VERSION ""

NS_ :

BS_:

BU_: IVI GTW IC HUD DVR WCM PDC VSP SVC TBOX_INFO SVM

BO_ 1957 Diag_Resp_IVI: 8 IVI
 SG_ Diag_Resp_IVI_Data : 0|64@1+ (1,0) [0|0] "N/A"  GTW

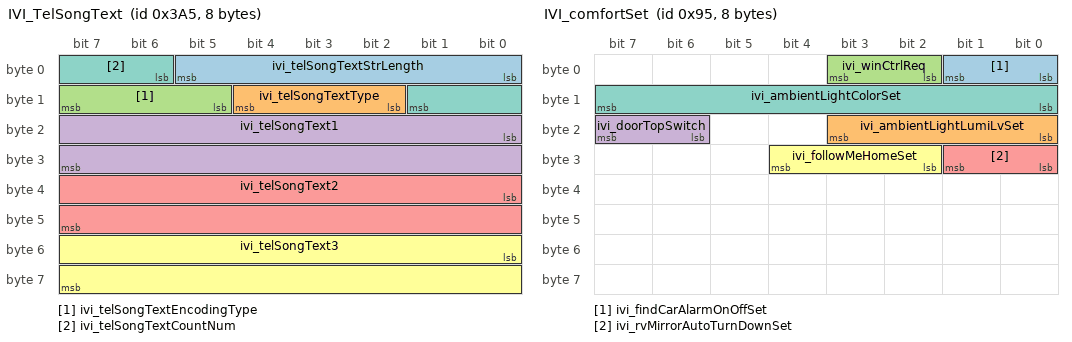
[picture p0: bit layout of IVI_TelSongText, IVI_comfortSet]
BO_ 933 IVI_TelSongText: 8 IVI
 SG_ ivi_telSongTextStrLength : 0|6@1+ (1,0) [0|63] ""  IC,HUD
 SG_ ivi_telSongTextType : 10|3@1+ (1,0) [0|7] ""  IC,HUD
 SG_ ivi_telSongTextEncodingType : 13|3@1+ (1,0) [0|7] ""  IC,HUD
 SG_ ivi_telSongText1 : 16|16@1+ (1,0) [0|65535] ""  IC,HUD
 SG_ ivi_telSongText2 : 32|16@1+ (1,0) [0|65535] ""  IC,HUD
 SG_ ivi_telSongText3 : 48|16@1+ (1,0) [0|65535] ""  IC,HUD
 SG_ ivi_telSongTextCountNum : 6|4@1+ (1,0) [0|15] ""  IC,HUD

BO_ 437 IVI_chassisSet: 8 IVI
 SG_ ivi_epsModeSet : 0|2@1+ (1,0) [0|3] ""  GTW
 SG_ ivi_lkaSensitivitySet : 10|2@1+ (1,0) [0|3] ""  GTW
 SG_ ivi_lcaBsdOnOffSet : 12|2@1+ (1,0) [0|3] ""  GTW
 SG_ ivi_rctaOnOffSet : 14|2@1+ (1,0) [0|3] ""  GTW
 SG_ ivi_dowOnOffSet : 16|2@1+ (1,0) [0|3] ""  GTW
 SG_ ivi_escOffSw : 2|2@1+ (1,0) [0|3] ""  GTW
 SG_ ivi_laneAssistFuncSet : 22|2@1+ (1,0) [0|3] ""  GTW
 SG_ ivi_hmaOnOffSet : 24|2@1+ (1,0) [0|3] ""  GTW
 SG_ ivi_slaOnOffSet : 26|2@1+ (1,0) [0|3] ""  GTW
 SG_ ivi_currentRoadType : 28|4@1+ (1,0) [0|15] ""  GTW
 SG_ ivi_countryCodeSet : 32|8@1+ (1,0) [0|255] ""  GTW
 SG_ ivi_hdcOnOffSet : 4|2@1+ (1,0) [0|3] ""  GTW
 SG_ ivi_speedLimitSet : 40|8@1+ (1,0) [0|130] ""  GTW
 SG_ ivi_speedLimitUnitSet : 48|2@1+ (1,0) [0|3] ""  GTW
 SG_ ivi_speedLimitStsSet : 50|2@1+ (1,0) [0|3] ""  GTW
 SG_ ivi_avhOnOffSet : 52|2@1+ (1,0) [0|3] ""  GTW
 SG_ ivi_pcwOnOffSet : 54|2@1+ (1,0) [0|3] ""  GTW
 SG_ ivi_accTJAICAFuncSet : 56|2@1+ (1,0) [0|3] ""  GTW
 SG_ ivi_lasWarningModeSelection : 58|2@1+ (1,0) [0|3] ""  GTW
 SG_ ivi_aebOnOffSet : 6|2@1+ (1,0) [0|3] ""  GTW
 SG_ ivi_trailerModeOnOffSet : 60|1@1+ (1,0) [0|1] ""  GTW
 SG_ ivi_trailerModeOnOffSetValid : 61|1@1+ (1,0) [0|1] ""  GTW

BO_ 149 IVI_comfortSet: 8 IVI
 SG_ ivi_findCarAlarmOnOffSet : 0|2@1+ (1,0) [0|3] ""  GTW
 SG_ ivi_ambientLightLumiLvSet : 16|4@1+ (1,0) [0|15] ""  GTW
 SG_ ivi_winCtrlReq : 2|2@1+ (1,0) [0|3] ""  GTW
 SG_ ivi_doorTopSwitch : 22|2@1+ (1,0) [0|3] ""  GTW
 SG_ ivi_rvMirrorAutoTurnDownSet : 24|2@1+ (1,0) [0|3] ""  GTW
 SG_ ivi_followMeHomeSet : 26|3@1+ (1,0) [0|7] ""  GTW
 SG_ ivi_ambientLightColorSet : 8|8@1+ (1,0) [0|255] ""  GTW

BO_ 117 IVI_control: 8 IVI
 SG_ ivi_hoodUnlockCtrl : 0|2@1+ (1,0) [0|3] ""  GTW
 SG_ ivi_lowBeamOnOffCtrl : 10|2@1+ (1,0) [0|3] ""  GTW
 SG_ ivi_highBeamOnOffCtrl : 12|2@1+ (1,0) [0|3] ""  GTW
 SG_ ivi_positionLampOnOffCtrl : 14|2@1+ (1,0) [0|3] ""  GTW
 SG_ ivi_autoLampOnOffCtrl : 16|2@1+ (1,0) [0|3] ""  GTW
 SG_ ivi_childLockCtrl : 2|2@1+ (1,0) [0|3] ""  GTW
 SG_ ivi_rearFogLampOnOffCtrl : 20|2@1+ (1,0) [0|3] ""  GTW
 SG_ ivi_chrgPortCapOpenCtrl : 24|2@1+ (1,0) [0|3] ""  GTW
 SG_ ivi_sunroofGlassCmd : 26|3@1+ (1,0) [0|7] ""  GTW
 SG_ ivi_svmOnOffCtrl : 30|2@1+ (1,0) [0|3] ""  GTW
 SG_ ivi_tailgateCtrl : 32|2@1+ (1,0) [0|3] ""  GTW
 SG_ ivi_rvMirrorFoldCtrl : 34|2@1+ (1,0) [0|3] ""  GTW
 SG_ ivi_rearDefrostCtrl : 36|2@1+ (1,0) [0|3] ""  GTW
 SG_ ivi_gloveBoxUnlockCtrl : 4|2@1+ (1,0) [0|3] ""  GTW
 SG_ ivi_windowLFCtrl : 40|2@1+ (1,0) [0|3] ""  GTW
 SG_ ivi_windowRFCtrl : 42|2@1+ (1,0) [0|3] ""  GTW
 SG_ ivi_windowLRCtrl : 44|2@1+ (1,0) [0|3] ""  GTW
 SG_ ivi_windowRRCtrl : 46|2@1+ (1,0) [0|3] ""  GTW
 SG_ ivi_approachingUnlockCtrl : 50|2@1+ (1,0) [0|3] ""  GTW
 SG_ ivi_awayUnlockCtrl : 52|2@1+ (1,0) [0|3] ""  GTW
 SG_ ivi_wipperMaintModeCtrl : 54|1@1+ (1,0) [0|1] ""  GTW
 SG_ ivi_nozzleHeatingStsCtrl : 56|2@1+ (1,0) [0|3] ""  GTW
 SG_ ivi_sunroofLightChangingCtrl : 58|2@1+ (1,0) [0|3] ""  GTW
 SG_ ivi_centralLockCtrl : 6|2@1+ (1,0) [0|3] ""  GTW
 SG_ ivi_frontWindshieldHeatingCtrl : 60|2@1+ (1,0) [0|3] ""  GTW
 SG_ ivi_lowVoltPowerCtrl : 62|2@1+ (1,0) [0|3] ""  GTW
 SG_ ivi_fuelPortCapOpenCtrl : 8|2@1+ (1,0) [0|3] ""  GTW

BO_ 197 IVI_infoSet: 8 IVI
 SG_ ivi_dvrRecordTimeSet : 0|2@1+ (1,0) [0|3] ""  DVR
 SG_ ivi_dvrCollideSensitivitySet : 13|2@1+ (1,0) [0|3] ""  DVR
 SG_ ivi_dvrFilePlayNum : 16|5@1+ (1,0) [0|31] ""  DVR
 SG_ ivi_dvrMuteRecordSet : 2|2@1+ (1,0) [0|3] ""  DVR
 SG_ ivi_themeSet : 21|3@1+ (1,0) [0|7] ""  IC
 SG_ ivi_wcmOnOffSet : 24|2@1+ (1,0) [0|3] ""  WCM
 SG_ ivi_pdcOnOffSet : 26|2@1+ (1,0) [0|3] ""  PDC
 SG_ ivi_minSocWarningSet : 32|8@1+ (0.5,0) [10|50] "%"  IC
 SG_ ivi_dvrRcrdQualitySet : 4|2@1+ (1,0) [0|3] ""  DVR
 SG_ ivi_maintenanceIndOnOffSet : 40|2@1+ (1,0) [0|3] ""  IC
 SG_ ivi_hudOnOffSet : 42|2@1+ (1,0) [0|3] ""  HUD
 SG_ ivi_vspOnOffSet : 44|2@1+ (1,0) [0|3] ""  VSP
 SG_ ivi_vsp_SoundConfigure : 46|2@1+ (1,0) [0|3] ""  VSP
 SG_ ivi_overspdWarningSet : 48|8@1+ (1,40) [40|260] "km/h"  IC
 SG_ ivi_IllumiSynSwitch : 56|2@1+ (1,0) [0|3] ""  IC
 SG_ ivi_IllumiLevelSet : 58|5@1+ (1,0) [0|31] ""  IC
 SG_ ivi_dvrParkingMonitorSet : 6|2@1+ (1,0) [0|3] ""  DVR
 SG_ ivi_dvrCommandList : 8|5@1+ (1,0) [0|31] ""  DVR

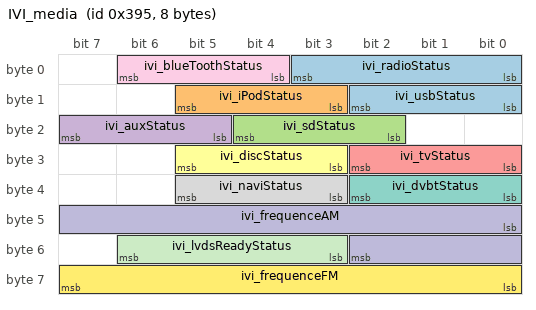
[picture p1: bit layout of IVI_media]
BO_ 917 IVI_media: 8 IVI
 SG_ ivi_radioStatus : 0|4@1+ (1,0) [0|15] ""  IC,HUD
 SG_ ivi_iPodStatus : 11|3@1+ (1,0) [0|7] ""  IC
 SG_ ivi_sdStatus : 18|3@1+ (1,0) [0|7] ""  IC
 SG_ ivi_auxStatus : 21|3@1+ (1,0) [0|7] ""  IC,HUD
 SG_ ivi_tvStatus : 24|3@1+ (1,0) [0|7] ""  IC
 SG_ ivi_discStatus : 27|3@1+ (1,0) [0|7] ""  IC
 SG_ ivi_dvbtStatus : 32|3@1+ (1,0) [0|7] ""  IC
 SG_ ivi_naviStatus : 35|3@1+ (1,0) [0|7] ""  IC,HUD
 SG_ ivi_blueToothStatus : 4|3@1+ (1,0) [0|7] ""  IC,HUD
 SG_ ivi_frequenceAM : 40|11@1+ (1,522) [522|1620] "KHZ"  IC,HUD
 SG_ ivi_lvdsReadyStatus : 51|4@1+ (1,0) [0|15] ""  IC
 SG_ ivi_frequenceFM : 56|8@1+ (0.1,87.5) [87.5|108] "MHZ"  IC,HUD
 SG_ ivi_usbStatus : 8|3@1+ (1,0) [0|7] ""  IC,HUD

BO_ 1157 IVI_navi: 8 IVI
 SG_ ivi_crossNaviMode : 0|7@1+ (1,0) [0|127] ""  IC,HUD
 SG_ ivi_naviDirection : 24|4@1+ (1,0) [0|8] ""  IC,HUD

CM_ " ";
CM_ SG_ 1957 Diag_Resp_IVI_Data "Diagnostic Physical Request Data from IVI";
CM_ SG_ 933 ivi_telSongTextStrLength "通话或歌曲信息文本长度.触发时以20ms周期发送，最多发送15帧.";
CM_ SG_ 933 ivi_telSongTextType "通话或歌曲信息文本类型";
CM_ SG_ 933 ivi_telSongTextEncodingType "通话或歌曲信息文本编码方式";
CM_ SG_ 933 ivi_telSongText1 "通话或歌曲信息信息文本1";
CM_ SG_ 933 ivi_telSongText2 "通话或歌曲信息信息文本2";
CM_ SG_ 933 ivi_telSongText3 "通话或歌曲信息信息文本2";
CM_ SG_ 933 ivi_telSongTextCountNum "通话或歌曲信息文本数据包编号";
CM_ SG_ 437 ivi_epsModeSet "EPS mode set.";
CM_ SG_ 437 ivi_lkaSensitivitySet "LKA sensitivity set.";
CM_ SG_ 437 ivi_lcaBsdOnOffSet "Lane change assist/Blind Spot Detection ON OFF set.";
CM_ SG_ 437 ivi_rctaOnOffSet "Rear CTA ON OFF set.";
CM_ SG_ 437 ivi_dowOnOffSet "Door open warning ON OFF set.";
CM_ SG_ 437 ivi_escOffSw "ESC off switch.";
CM_ SG_ 437 ivi_laneAssistFuncSet "Lane assist function set.";
CM_ SG_ 437 ivi_hmaOnOffSet "High Beam Assist ON OFF set.";
CM_ SG_ 437 ivi_slaOnOffSet "Speed limit assist ON OFF set.";
CM_ SG_ 437 ivi_currentRoadType "Current road type.";
CM_ SG_ 437 ivi_countryCodeSet "Country code set.";
CM_ SG_ 437 ivi_hdcOnOffSet "HDC ON OFF set.";
CM_ SG_ 437 ivi_speedLimitSet "Speed Limit set.";
CM_ SG_ 437 ivi_speedLimitUnitSet "Speed Limit Unit set.";
CM_ SG_ 437 ivi_speedLimitStsSet "Speed Limit Status set.";
CM_ SG_ 437 ivi_avhOnOffSet "AVH ON OFF set.";
CM_ SG_ 437 ivi_pcwOnOffSet "PCW ON OFF set.";
CM_ SG_ 437 ivi_accTJAICAFuncSet "ACC and TJA/ICA function select.";
CM_ SG_ 437 ivi_lasWarningModeSelection "LAS Warning Mode Set";
CM_ SG_ 437 ivi_aebOnOffSet "AEB ON OFF set.";
CM_ SG_ 437 ivi_trailerModeOnOffSet "Trailer mode ON OFF set.";
CM_ SG_ 437 ivi_trailerModeOnOffSetValid "Trailer mode ON OFF set signal valid.";
CM_ SG_ 149 ivi_findCarAlarmOnOffSet "Find car alarm on off set.";
CM_ SG_ 149 ivi_ambientLightLumiLvSet "Ambient light luminance level set.";
CM_ SG_ 149 ivi_winCtrlReq "IVI window control request.";
CM_ SG_ 149 ivi_doorTopSwitch "门顶开关";
CM_ SG_ 149 ivi_rvMirrorAutoTurnDownSet "Rearview mirror auto turn down on off set.";
CM_ SG_ 149 ivi_followMeHomeSet "Follow me home function set.";
CM_ SG_ 149 ivi_ambientLightColorSet "Ambient light color set.";
CM_ SG_ 117 ivi_hoodUnlockCtrl "Hood unlock control.";
CM_ SG_ 117 ivi_lowBeamOnOffCtrl "Low beam on off control.";
CM_ SG_ 117 ivi_highBeamOnOffCtrl "High beam on off control.(reserved)";
CM_ SG_ 117 ivi_positionLampOnOffCtrl "Position lamp on off control.";
CM_ SG_ 117 ivi_autoLampOnOffCtrl "Auto lamp on off control.(reserved)";
CM_ SG_ 117 ivi_childLockCtrl "Child safety lock control.";
CM_ SG_ 117 ivi_rearFogLampOnOffCtrl "Rear fog lamp on off control.(reserved)";
CM_ SG_ 117 ivi_chrgPortCapOpenCtrl "Charging port cap open control.";
CM_ SG_ 117 ivi_sunroofGlassCmd "天窗控制命令";
CM_ SG_ 117 ivi_svmOnOffCtrl "SVM on off control.";
CM_ SG_ 117 ivi_tailgateCtrl "Tailgate control.";
CM_ SG_ 117 ivi_rvMirrorFoldCtrl "Rearview mirror fold unfold control.";
CM_ SG_ 117 ivi_rearDefrostCtrl "Rear defrost control.";
CM_ SG_ 117 ivi_gloveBoxUnlockCtrl "glove box unlock control";
CM_ SG_ 117 ivi_windowLFCtrl "Left front window control.";
CM_ SG_ 117 ivi_windowRFCtrl "Right front window control.";
CM_ SG_ 117 ivi_windowLRCtrl "Left rear window control.";
CM_ SG_ 117 ivi_windowRRCtrl "Right rear window control.";
CM_ SG_ 117 ivi_approachingUnlockCtrl "approaching unlock control";
CM_ SG_ 117 ivi_awayUnlockCtrl "away unlock control";
CM_ SG_ 117 ivi_wipperMaintModeCtrl "控制雨刮进入维修模式档位信号";
CM_ SG_ 117 ivi_nozzleHeatingStsCtrl "控制喷嘴加热和关闭加热信号";
CM_ SG_ 117 ivi_sunroofLightChangingCtrl "调光玻璃顶";
CM_ SG_ 117 ivi_centralLockCtrl "Central lock control.";
CM_ SG_ 117 ivi_frontWindshieldHeatingCtrl "前挡风玻璃加热";
CM_ SG_ 117 ivi_lowVoltPowerCtrl "低压电源开关信号";
CM_ SG_ 117 ivi_fuelPortCapOpenCtrl "Fuel port cap open close control.";
CM_ SG_ 197 ivi_dvrRecordTimeSet "DVR record time set.
设置DVR录制时间";
CM_ SG_ 197 ivi_dvrCollideSensitivitySet "DVR collide sensitivity set.
设置DVR监控灵敏度";
CM_ SG_ 197 ivi_dvrFilePlayNum "DVR file play number select.
DVR文件播放选择";
CM_ SG_ 197 ivi_dvrMuteRecordSet "DVR voice record set.
DVR录音功能设置";
CM_ SG_ 197 ivi_themeSet "Theme mode set.";
CM_ SG_ 197 ivi_wcmOnOffSet "WCM ON OFF set.";
CM_ SG_ 197 ivi_pdcOnOffSet "PDC ON OFF set.";
CM_ SG_ 197 ivi_minSocWarningSet "Mininum SOC warning value set.";
CM_ SG_ 197 ivi_dvrRcrdQualitySet "DVR video record resolution set.
DVR录制视频分辨率设置";
CM_ SG_ 197 ivi_maintenanceIndOnOffSet "Maintenance indication  ON OFF set.";
CM_ SG_ 197 ivi_hudOnOffSet "HUD ON OFF set.";
CM_ SG_ 197 ivi_vspOnOffSet "VSP ON OFF set.";
CM_ SG_ 197 ivi_vsp_SoundConfigure "vsp_SoundConfigure";
CM_ SG_ 197 ivi_overspdWarningSet "Overspeed  warning value set.";
CM_ SG_ 197 ivi_IllumiSynSwitch "illumination synchronization switch status
亮度同步开关信号";
CM_ SG_ 197 ivi_IllumiLevelSet "illumination level set";
CM_ SG_ 197 ivi_dvrParkingMonitorSet "DVR parking monitor set.
DVR停车监控设置";
CM_ SG_ 197 ivi_dvrCommandList "DVR commond list.
DVR控制命令列表";
CM_ SG_ 917 ivi_radioStatus "收音机连接状态";
CM_ SG_ 917 ivi_iPodStatus "iPod连接状态";
CM_ SG_ 917 ivi_sdStatus "SD连接状态";
CM_ SG_ 917 ivi_auxStatus "AUX连接状态";
CM_ SG_ 917 ivi_tvStatus "TV连接状态";
CM_ SG_ 917 ivi_discStatus "DISC连接状态";
CM_ SG_ 917 ivi_dvbtStatus "DVBT连接状态";
CM_ SG_ 917 ivi_naviStatus "导航连接状态";
CM_ SG_ 917 ivi_blueToothStatus "蓝牙连接状态";
CM_ SG_ 917 ivi_frequenceAM "IVI主机AM频率(接收无效值时不显示)";
CM_ SG_ 917 ivi_lvdsReadyStatus "当前LVDS画面是否准备就绪";
CM_ SG_ 917 ivi_frequenceFM "IVI主机FM频率(接收无效值时不显示)";
CM_ SG_ 917 ivi_usbStatus "USB连接状态";
CM_ SG_ 1157 ivi_crossNaviMode "导航转向模式";
CM_ SG_ 1157 ivi_naviDirection "导航方向";
BA_DEF_ SG_  "GenSigFilterAlgorithm" ENUM  "Always","Never","MaskNewEquX";
BA_DEF_ SG_  "GenSigSendType" ENUM  "Pending","Triggered";
BA_DEF_ BU_  "ILUsed" ENUM  "No","Yes";
BA_DEF_ BU_  "NmAsrCanMsgReducedTime" INT 320 640;
BA_DEF_ BU_  "TpSTMin" INT 0 255;
BA_DEF_  "Baudrate" INT 0 1000000;
BA_DEF_  "BusType" STRING ;
BA_DEF_  "Manufacturer" STRING ;
BA_DEF_  "NmAsrBaseAddress" HEX 0 2047;
BA_DEF_  "NmAsrCanMsgCycleTime" INT 0 65535;
BA_DEF_  "NmAsrMessageCount" INT 0 256;
BA_DEF_  "NmAsrRepeatMessageTime" INT 0 65535;
BA_DEF_  "NmAsrTimeoutTime" INT 0 65535;
BA_DEF_  "NmAsrWaitBusSleepTime" INT 0 65535;
BA_DEF_ BO_  "DiagRequest" ENUM  "No","Yes";
BA_DEF_ BO_  "DiagResponse" ENUM  "No","Yes";
BA_DEF_ BO_  "DiagState" ENUM  "No","Yes";
BA_DEF_ BO_  "GenMsgCycleTime" INT 0 0;
BA_DEF_ BO_  "GenMsgCycleTimeFast" INT 0 0;
BA_DEF_ BO_  "GenMsgILSupport" ENUM  "No","Yes";
BA_DEF_ BO_  "GenMsgNrOfRepetition" INT 0 0;
BA_DEF_ BO_  "GenMsgSendType" ENUM  "Direct","Mixed","Periodic";
BA_DEF_ BO_  "GenMsgTimeout" INT 0 0;
BA_DEF_  "DBName" STRING ;
BA_DEF_ SG_  "SystemSignalLongSymbol" STRING ;
BA_DEF_DEF_  "GenSigFilterAlgorithm" "Always";
BA_DEF_DEF_  "GenSigSendType" "Pending";
BA_DEF_DEF_  "ILUsed" "Yes";
BA_DEF_DEF_  "NmAsrCanMsgReducedTime" 320;
BA_DEF_DEF_  "TpSTMin" 10;
BA_DEF_DEF_  "Baudrate" 500000;
BA_DEF_DEF_  "BusType" "CAN";
BA_DEF_DEF_  "Manufacturer" "HSAE";
BA_DEF_DEF_  "NmAsrBaseAddress" 1280;
BA_DEF_DEF_  "NmAsrCanMsgCycleTime" 1;
BA_DEF_DEF_  "NmAsrMessageCount" 128;
BA_DEF_DEF_  "NmAsrRepeatMessageTime" 3200;
BA_DEF_DEF_  "NmAsrTimeoutTime" 2000;
BA_DEF_DEF_  "NmAsrWaitBusSleepTime" 1500;
BA_DEF_DEF_  "DiagRequest" "No";
BA_DEF_DEF_  "DiagResponse" "No";
BA_DEF_DEF_  "DiagState" "No";
BA_DEF_DEF_  "GenMsgCycleTime" 0;
BA_DEF_DEF_  "GenMsgCycleTimeFast" 0;
BA_DEF_DEF_  "GenMsgILSupport" "Yes";
BA_DEF_DEF_  "GenMsgNrOfRepetition" 0;
BA_DEF_DEF_  "GenMsgSendType" "Periodic";
BA_DEF_DEF_  "GenMsgTimeout" 0;
BA_DEF_DEF_  "DBName" "";
BA_DEF_DEF_  "SystemSignalLongSymbol" "";
BA_ "DBName" "INFOCAN";
BA_ "GenMsgSendType" BO_ 1957 0;
BA_ "GenMsgILSupport" BO_ 1957 0;
BA_ "DiagState" BO_ 1957 1;
BA_ "DiagResponse" BO_ 1957 1;
BA_ "GenMsgTimeout" BO_ 933 4000;
BA_ "GenMsgCycleTime" BO_ 933 400;
BA_ "GenMsgTimeout" BO_ 437 100;
BA_ "GenMsgCycleTime" BO_ 437 10;
BA_ "GenMsgSendType" BO_ 149 0;
BA_ "GenMsgNrOfRepetition" BO_ 149 3;
BA_ "GenMsgCycleTimeFast" BO_ 149 50;
BA_ "GenMsgTimeout" BO_ 117 1000;
BA_ "GenMsgSendType" BO_ 117 1;
BA_ "GenMsgNrOfRepetition" BO_ 117 3;
BA_ "GenMsgCycleTimeFast" BO_ 117 50;
BA_ "GenMsgCycleTime" BO_ 117 100;
BA_ "GenMsgTimeout" BO_ 197 1000;
BA_ "GenMsgSendType" BO_ 197 1;
BA_ "GenMsgNrOfRepetition" BO_ 197 3;
BA_ "GenMsgCycleTimeFast" BO_ 197 50;
BA_ "GenMsgCycleTime" BO_ 197 100;
BA_ "GenMsgTimeout" BO_ 917 1000;
BA_ "GenMsgCycleTime" BO_ 917 100;
BA_ "GenMsgTimeout" BO_ 1157 5000;
BA_ "GenMsgCycleTime" BO_ 1157 500;
BA_ "GenSigSendType" SG_ 1957 Diag_Resp_IVI_Data 1;
BA_ "GenSigSendType" SG_ 149 ivi_findCarAlarmOnOffSet 1;
BA_ "GenSigSendType" SG_ 149 ivi_ambientLightLumiLvSet 1;
BA_ "GenSigSendType" SG_ 149 ivi_winCtrlReq 1;
BA_ "GenSigSendType" SG_ 149 ivi_doorTopSwitch 1;
BA_ "GenSigSendType" SG_ 149 ivi_rvMirrorAutoTurnDownSet 1;
BA_ "GenSigSendType" SG_ 149 ivi_followMeHomeSet 1;
BA_ "GenSigSendType" SG_ 149 ivi_ambientLightColorSet 1;
VAL_ 933 ivi_telSongTextStrLength 63 "Reserved" 62 "Reserved" 61 "Reserved" 60 "Reserved" 59 "Reserved" 58 "Reserved" 57 "Reserved" 56 "Reserved" 55 "Reserved" 54 "Reserved" 53 "Reserved" 52 "Reserved" 51 "Reserved" 50 "Reserved" 49 "Reserved" 48 "Reserved" 47 "Reserved" 46 "信息保持" 45 "文本长度1~45" 44 "文本长度1~45" 43 "文本长度1~45" 42 "文本长度1~45" 41 "文本长度1~45" 40 "文本长度1~45" 39 "文本长度1~45" 38 "文本长度1~45" 37 "文本长度1~45" 36 "文本长度1~45" 35 "文本长度1~45" 34 "文本长度1~45" 33 "文本长度1~45" 32 "文本长度1~45" 31 "文本长度1~45" 30 "文本长度1~45" 29 "文本长度1~45" 28 "文本长度1~45" 27 "文本长度1~45" 26 "文本长度1~45" 25 "文本长度1~45" 24 "文本长度1~45" 23 "文本长度1~45" 22 "文本长度1~45" 21 "文本长度1~45" 20 "文本长度1~45" 19 "文本长度1~45" 18 "文本长度1~45" 17 "文本长度1~45" 16 "文本长度1~45" 15 "文本长度1~45" 14 "文本长度1~45" 13 "文本长度1~45" 12 "文本长度1~45" 11 "文本长度1~45" 10 "文本长度1~45" 9 "文本长度1~45" 8 "文本长度1~45" 7 "文本长度1~45" 6 "文本长度1~45" 5 "文本长度1~45" 4 "文本长度1~45" 3 "文本长度1~45" 2 "文本长度1~45" 1 "文本长度1~45" 0 "ON INFO" ;
VAL_ 933 ivi_telSongTextType 3 "蓝牙电话号码文本" 2 "蓝牙通话人姓名文本" 1 "歌曲相关信息" 0 "NULL" ;
VAL_ 933 ivi_telSongTextEncodingType 5 "GBK" 4 "UNICODE大端模式" 3 "NICODE小端模式" 2 "AUTF-8" 1 "ASCII" 0 "NULL" ;
VAL_ 933 ivi_telSongTextCountNum 15 "数据包编号1~15" 14 "数据包编号1~15" 13 "数据包编号1~15" 12 "数据包编号1~15" 11 "数据包编号1~15" 10 "数据包编号1~15" 9 "数据包编号1~15" 8 "数据包编号1~15" 7 "数据包编号1~15" 6 "数据包编号1~15" 5 "数据包编号1~15" 4 "数据包编号1~15" 3 "数据包编号1~15" 2 "数据包编号1~15" 1 "数据包编号1~15" 0 "Default" ;
VAL_ 437 ivi_epsModeSet 3 "INVALID" 2 "SPORT" 1 "COMFORT" 0 "STANDARD" ;
VAL_ 437 ivi_lkaSensitivitySet 3 "INVALID" 2 "HIGH" 1 "NORMAL" 0 "LOW" ;
VAL_ 437 ivi_lcaBsdOnOffSet 3 "INVALID" 1 "ON" 0 "OFF" ;
VAL_ 437 ivi_rctaOnOffSet 3 "INVALID" 1 "ON" 0 "OFF" ;
VAL_ 437 ivi_dowOnOffSet 3 "INVALID" 1 "ON" 0 "OFF" ;
VAL_ 437 ivi_escOffSw 3 "INVALID" 1 "ON" 0 "OFF" ;
VAL_ 437 ivi_laneAssistFuncSet 3 "LDW+LKA" 2 "LDW+RDP" 1 "LDW" 0 "OFF" ;
VAL_ 437 ivi_hmaOnOffSet 3 "INVALID" 1 "ON" 0 "OFF" ;
VAL_ 437 ivi_slaOnOffSet 3 "INVALID" 1 "ON" 0 "OFF" ;
VAL_ 437 ivi_hdcOnOffSet 3 "INVALID" 1 "ON" 0 "OFF" ;
VAL_ 437 ivi_speedLimitSet 130 "SPL 130" 2 "SPL 2" 1 "SPL 1" 0 "No Display" ;
VAL_ 437 ivi_speedLimitUnitSet 2 "KPH" 1 "MPH" 0 "Unknown" ;
VAL_ 437 ivi_speedLimitStsSet 3 "SL_PLURUAL" 2 "SL_NOLIMIT" 1 "SL_EXISTS" 0 "SL_UNKNOWN" ;
VAL_ 437 ivi_avhOnOffSet 3 "INVALID" 1 "ON" 0 "OFF" ;
VAL_ 437 ivi_pcwOnOffSet 3 "INVALID" 1 "ON" 0 "OFF" ;
VAL_ 437 ivi_accTJAICAFuncSet 3 "RESERVED" 2 "INVALID" 1 "TJA/ICA" 0 "ACC" ;
VAL_ 437 ivi_lasWarningModeSelection 3 "Voice+Voice+Vibration" 2 "Voice+Vibration" 1 "Vision+Voice" 0 "Only Vision" ;
VAL_ 437 ivi_aebOnOffSet 3 "INVALID" 1 "ON" 0 "OFF" ;
VAL_ 437 ivi_trailerModeOnOffSet 1 "TRAILER_MODE_ON" 0 "TRAILER_MODE_OFF" ;
VAL_ 437 ivi_trailerModeOnOffSetValid 1 "VALID" 0 "INVALID" ;
VAL_ 149 ivi_findCarAlarmOnOffSet 3 "INVALID" 2 "ALARM" 1 "NO_ALARM" 0 "NO_COMMAND" ;
VAL_ 149 ivi_ambientLightLumiLvSet 11 "LV10" 10 "LV9" 9 "LV8" 8 "LV7" 7 "LV6" 6 "LV5_NORMAL" 5 "LV4" 4 "LV3" 3 "LV2" 2 "LV1" 1 "LV0" 0 "NO_COMMAND" ;
VAL_ 149 ivi_winCtrlReq 2 "WIN_DOWN" 1 "WIN_UP" 0 "NO_REQUEST" ;
VAL_ 149 ivi_doorTopSwitch 3 "INVALID" 2 "ON" 1 "OFF" 0 "NO_COMMAND" ;
VAL_ 149 ivi_rvMirrorAutoTurnDownSet 3 "INVALID" 2 "ON" 1 "OFF" 0 "NO_COMMAND" ;
VAL_ 149 ivi_followMeHomeSet 7 "INVALID" 4 "60S" 3 "30S" 2 "15S" 1 "OFF" 0 "NO_COMMAND" ;
VAL_ 149 ivi_ambientLightColorSet 0 "Invalid" ;
VAL_ 117 ivi_hoodUnlockCtrl 3 "INVALID" 2 "RESERVED" 1 "UNLOCK" 0 "NO_COMMAND" ;
VAL_ 117 ivi_lowBeamOnOffCtrl 3 "INVALID" 2 "ON" 1 "OFF" 0 "NO_COMMAND" ;
VAL_ 117 ivi_highBeamOnOffCtrl 3 "INVALID" 2 "ON" 1 "OFF" 0 "NO_COMMAND" ;
VAL_ 117 ivi_positionLampOnOffCtrl 3 "INVALID" 2 "ON" 1 "OFF" 0 "NO_COMMAND" ;
VAL_ 117 ivi_autoLampOnOffCtrl 3 "INVALID" 2 "ON" 1 "OFF" 0 "NO_COMMAND" ;
VAL_ 117 ivi_childLockCtrl 3 "INVALID" 2 "LOCK" 1 "UNLOCK" 0 "NO_COMMAND" ;
VAL_ 117 ivi_rearFogLampOnOffCtrl 3 "INVALID" 2 "ON" 1 "OFF" 0 "NO_COMMAND" ;
VAL_ 117 ivi_chrgPortCapOpenCtrl 3 "INVALID" 2 "RESERVED" 1 "OPEN" 0 "NO_COMMAND" ;
VAL_ 117 ivi_sunroofGlassCmd 7 "STOP_SUNSHADE" 6 "CLOSE_SUNSHAGE" 5 "OPEN_SUNSHADE" 4 "TILTUP_GLASS" 3 "STOP_GLASS" 2 "CLOSE_GLASS" 1 "OPEN_GLASS" 0 "NO_CMD" ;
VAL_ 117 ivi_svmOnOffCtrl 3 "INVALID" 2 "ON" 1 "OFF" 0 "NO_COMMAND" ;
VAL_ 117 ivi_tailgateCtrl 3 "STOP" 2 "OPEN" 1 "CLOSE" 0 "NO_COMMAND" ;
VAL_ 117 ivi_rvMirrorFoldCtrl 2 "UNFOLD" 1 "FOLD" 0 "NO_COMMAND" ;
VAL_ 117 ivi_rearDefrostCtrl 3 "INVALID" 2 "ON" 1 "OFF" 0 "NO_COMMAND" ;
VAL_ 117 ivi_gloveBoxUnlockCtrl 3 "INVALID" 2 "LOCK" 1 "UNLOCK" 0 "NO_COMMAND" ;
VAL_ 117 ivi_windowLFCtrl 3 "WINDOW_DOWN" 2 "WINDOW_UP" 1 "WINDOW_STOP" 0 "NONE" ;
VAL_ 117 ivi_windowRFCtrl 3 "WINDOW_DOWN" 2 "WINDOW_UP" 1 "WINDOW_STOP" 0 "NONE" ;
VAL_ 117 ivi_windowLRCtrl 3 "WINDOW_DOWN" 2 "WINDOW_UP" 1 "WINDOW_STOP" 0 "NONE" ;
VAL_ 117 ivi_windowRRCtrl 3 "WINDOW_DOWN" 2 "WINDOW_UP" 1 "WINDOW_STOP" 0 "NONE" ;
VAL_ 117 ivi_approachingUnlockCtrl 3 "INVALID" 2 "LOCK" 1 "UNLOCK" 0 "NO_COMMAND" ;
VAL_ 117 ivi_awayUnlockCtrl 3 "INVALID" 2 "LOCK" 1 "UNLOCK" 0 "NO_COMMAND" ;
VAL_ 117 ivi_wipperMaintModeCtrl 1 "REQUESTED" 0 "NO_REQUEST" ;
VAL_ 117 ivi_nozzleHeatingStsCtrl 3 "INVALID" 2 "ON" 1 "OFF" 0 "NO_COMMAND" ;
VAL_ 117 ivi_sunroofLightChangingCtrl 3 "INVALID" 2 "ON" 1 "OFF" 0 "NO_COMMAND" ;
VAL_ 117 ivi_centralLockCtrl 3 "INVALID" 2 "LOCK" 1 "UNLOCK" 0 "NO_COMMAND" ;
VAL_ 117 ivi_frontWindshieldHeatingCtrl 3 "INVALID" 2 "ON" 1 "OFF" 0 "NO_COMMAND" ;
VAL_ 117 ivi_lowVoltPowerCtrl 3 "INVALID" 2 "POWER ON REQUEST" 1 "POWER OFF REQUEST" 0 "NO_COMMAND" ;
VAL_ 117 ivi_fuelPortCapOpenCtrl 3 "INVALID" 2 "RESERVED_FUELPORT" 1 "OPEN_FUELPORT" 0 "NO_COMMAND_FUELPORT" ;
VAL_ 197 ivi_dvrRecordTimeSet 3 "5_MINUTES" 2 "3_MINUTES" 1 "1_MINUTE" 0 "INITIAL" ;
VAL_ 197 ivi_dvrCollideSensitivitySet 3 "INVALID" 2 "HIGH_SENSITIVITY" 1 "MID_SENSITIVITY" 0 "LOW_SENSITIVITY" ;
VAL_ 197 ivi_dvrFilePlayNum 31 "INVALID" 25 "SELECT_9" 24 "SELECT_8" 23 "SELECT_7" 22 "SELECT_6" 21 "SELECT_5" 20 "SELECT_4" 19 "SELECT_3" 18 "SELECT_2" 17 "SELECT_1" 9 "PLAY_FILE_9" 8 "PLAY_FILE_8" 7 "PLAY_FILE_7" 6 "PLAY_FILE_6" 5 "PLAY_FILE_5" 4 "PLAY_FILE_4" 3 "PLAY_FILE_3" 2 "PLAY_FILE_2" 1 "PLAY_FILE_1" ;
VAL_ 197 ivi_dvrMuteRecordSet 3 "INVALID" 2 "VOICE_REC_ON" 1 "VOICE_REC_OFF" 0 "INITIAL" ;
VAL_ 197 ivi_themeSet 7 "INVALID" 5 "SPORT" 4 "COMFORT" 3 "COMMON" 2 "ECO" 1 "CROSSLINE_DRIVING" 0 "NONE" ;
VAL_ 197 ivi_wcmOnOffSet 3 "INVALID" 1 "ON" 0 "OFF" ;
VAL_ 197 ivi_pdcOnOffSet 3 "INVALID" 1 "ON" 0 "OFF" ;
VAL_ 197 ivi_minSocWarningSet 255 "Invalid" ;
VAL_ 197 ivi_dvrRcrdQualitySet 3 "INVALID" 2 "720P_30FPS" 1 "1080P_30FPS" 0 "INITIAL" ;
VAL_ 197 ivi_maintenanceIndOnOffSet 3 "INVALID" 1 "ON" 0 "OFF" ;
VAL_ 197 ivi_hudOnOffSet 3 "NO_COMMAND" 2 "RESERVED" 1 "ON" 0 "OFF" ;
VAL_ 197 ivi_vspOnOffSet 3 "INVALID" 1 "ON" 0 "OFF" ;
VAL_ 197 ivi_vsp_SoundConfigure 3 "sound 3" 2 "sound 2" 1 "sound 1" 0 "default" ;
VAL_ 197 ivi_overspdWarningSet 255 "Invalid" ;
VAL_ 197 ivi_IllumiSynSwitch 3 "INVALID" 2 "RESERVED" 1 "ON" 0 "OFF" ;
VAL_ 197 ivi_IllumiLevelSet 31 "LEVEL31" 30 "LEVEL30" 29 "LEVEL29" 28 "LEVEL28" 27 "LEVEL27" 26 "LEVEL26" 25 "LEVEL25" 24 "LEVEL24" 23 "LEVEL23" 22 "LEVEL22" 21 "LEVEL21" 20 "LEVEL20" 19 "LEVEL19" 18 "LEVEL18" 17 "LEVEL17" 16 "LEVEL16" 15 "LEVEL15" 14 "LEVEL14" 13 "LEVEL13" 12 "LEVEL12" 11 "LEVEL11" 10 "LEVEL10" 9 "LEVEL9" 8 "LEVEL8" 7 "LEVEL7" 6 "LEVEL6" 5 "LEVEL5" 4 "LEVEL4" 3 "LEVEL3" 2 "LEVEL2" 1 "LEVEL1" 0 "INVALID" ;
VAL_ 197 ivi_dvrParkingMonitorSet 3 "INVALID" 2 "PARK_MONITOR_ON" 1 "PARK_MONITOR_OFF" 0 "INITIAL" ;
VAL_ 197 ivi_dvrCommandList 31 "INVALID" 22 "ENTER_UPDATE_MODE" 21 "NEXT_PAGE" 20 "PRE_PAGE" 19 "CANCEL" 18 "SELECT_ALL" 17 "EXIT_PLAY" 16 "PLAY_NEXT_FILE" 15 "PLAY_PREV_FILE" 13 "FILE_PLAY_PAUSE" 12 "VIDEO_RECORD_FUNC_ON" 11 "DELETE_FILE" 10 "MOVE_FILE" 9 "TAKE_PIC" 8 "FACTORY_RESET" 7 "ENTER_PIC_FOLDER" 6 "SDCARD_FORMAT" 5 "ENTER_URGENCY_VIDEO_FOLDER" 4 "ENTER_REALTIME_VIDEO_FOLDER" 3 "ENTER_URGENCY_RECORD" 2 "STOP_RECORD" 1 "ENTER_REALTIME_RECORD" 0 "INITIAL" ;
VAL_ 917 ivi_radioStatus 7 "TRACK REPEAT" 6 "TRACK RANDOM" 5 "TRACK SCAN" 4 "AUTO SEARCH" 3 "FREQUENCY SCAN" 2 "AM" 1 "FM" 0 "UNCONNECTED" ;
VAL_ 917 ivi_iPodStatus 2 "PLAY" 1 "CONNECTED" 0 "UNCONNECTED" ;
VAL_ 917 ivi_sdStatus 2 "PLAY" 1 "CONNECTED" 0 "UNCONNECTED" ;
VAL_ 917 ivi_auxStatus 2 "PLAY" 1 "CONNECTED" 0 "UNCONNECTED" ;
VAL_ 917 ivi_tvStatus 2 "PLAY" 1 "CONNECTED" 0 "UNCONNECTED" ;
VAL_ 917 ivi_discStatus 2 "PLAY" 1 "CONNECTED" 0 "UNCONNECTED" ;
VAL_ 917 ivi_dvbtStatus 2 "PLAY" 1 "CONNECTED" 0 "UNCONNECTED" ;
VAL_ 917 ivi_naviStatus 2 "ACTIVE（开始导航）" 1 "CONNECTED" 0 "UNCONNECTED" ;
VAL_ 917 ivi_blueToothStatus 6 "BT HANG UP" 5 "BT HOLDING" 4 "BT CALLING" 3 "MUSIC" 2 "RESERVED" 1 "CONNECTED" 0 "UNCONNECTED" ;
VAL_ 917 ivi_frequenceAM 2047 "Invalid" ;
VAL_ 917 ivi_lvdsReadyStatus 15 "预留" 14 "预留" 13 "预留" 12 "预留" 11 "预留" 10 "预留" 9 "预留" 8 "预留" 7 "预留" 6 "LVDS信号显示屏蔽（被其他界面打断）" 5 "收音机" 4 "多媒体" 3 "电话" 2 "全屏导航" 1 "小图标导航" 0 "0未就绪" ;
VAL_ 917 ivi_frequenceFM 255 "Invalid" ;
VAL_ 917 ivi_usbStatus 2 "PLAY" 1 "CONNECTED" 0 "UNCONNECTED" ;
VAL_ 1157 ivi_crossNaviMode 0 "参见附表“高德导航转向图标-替代灵图”" ;
VAL_ 1157 ivi_naviDirection 15 "INVALID" 14 "INVALID" 13 "INVALID" 12 "INVALID" 11 "INVALID" 10 "INVALID" 9 "INVALID" 8 "西北" 7 "西南" 6 "东北" 5 "东南" 4 "北" 3 "西" 2 "南" 1 "东" 0 "导航未开启" ;
